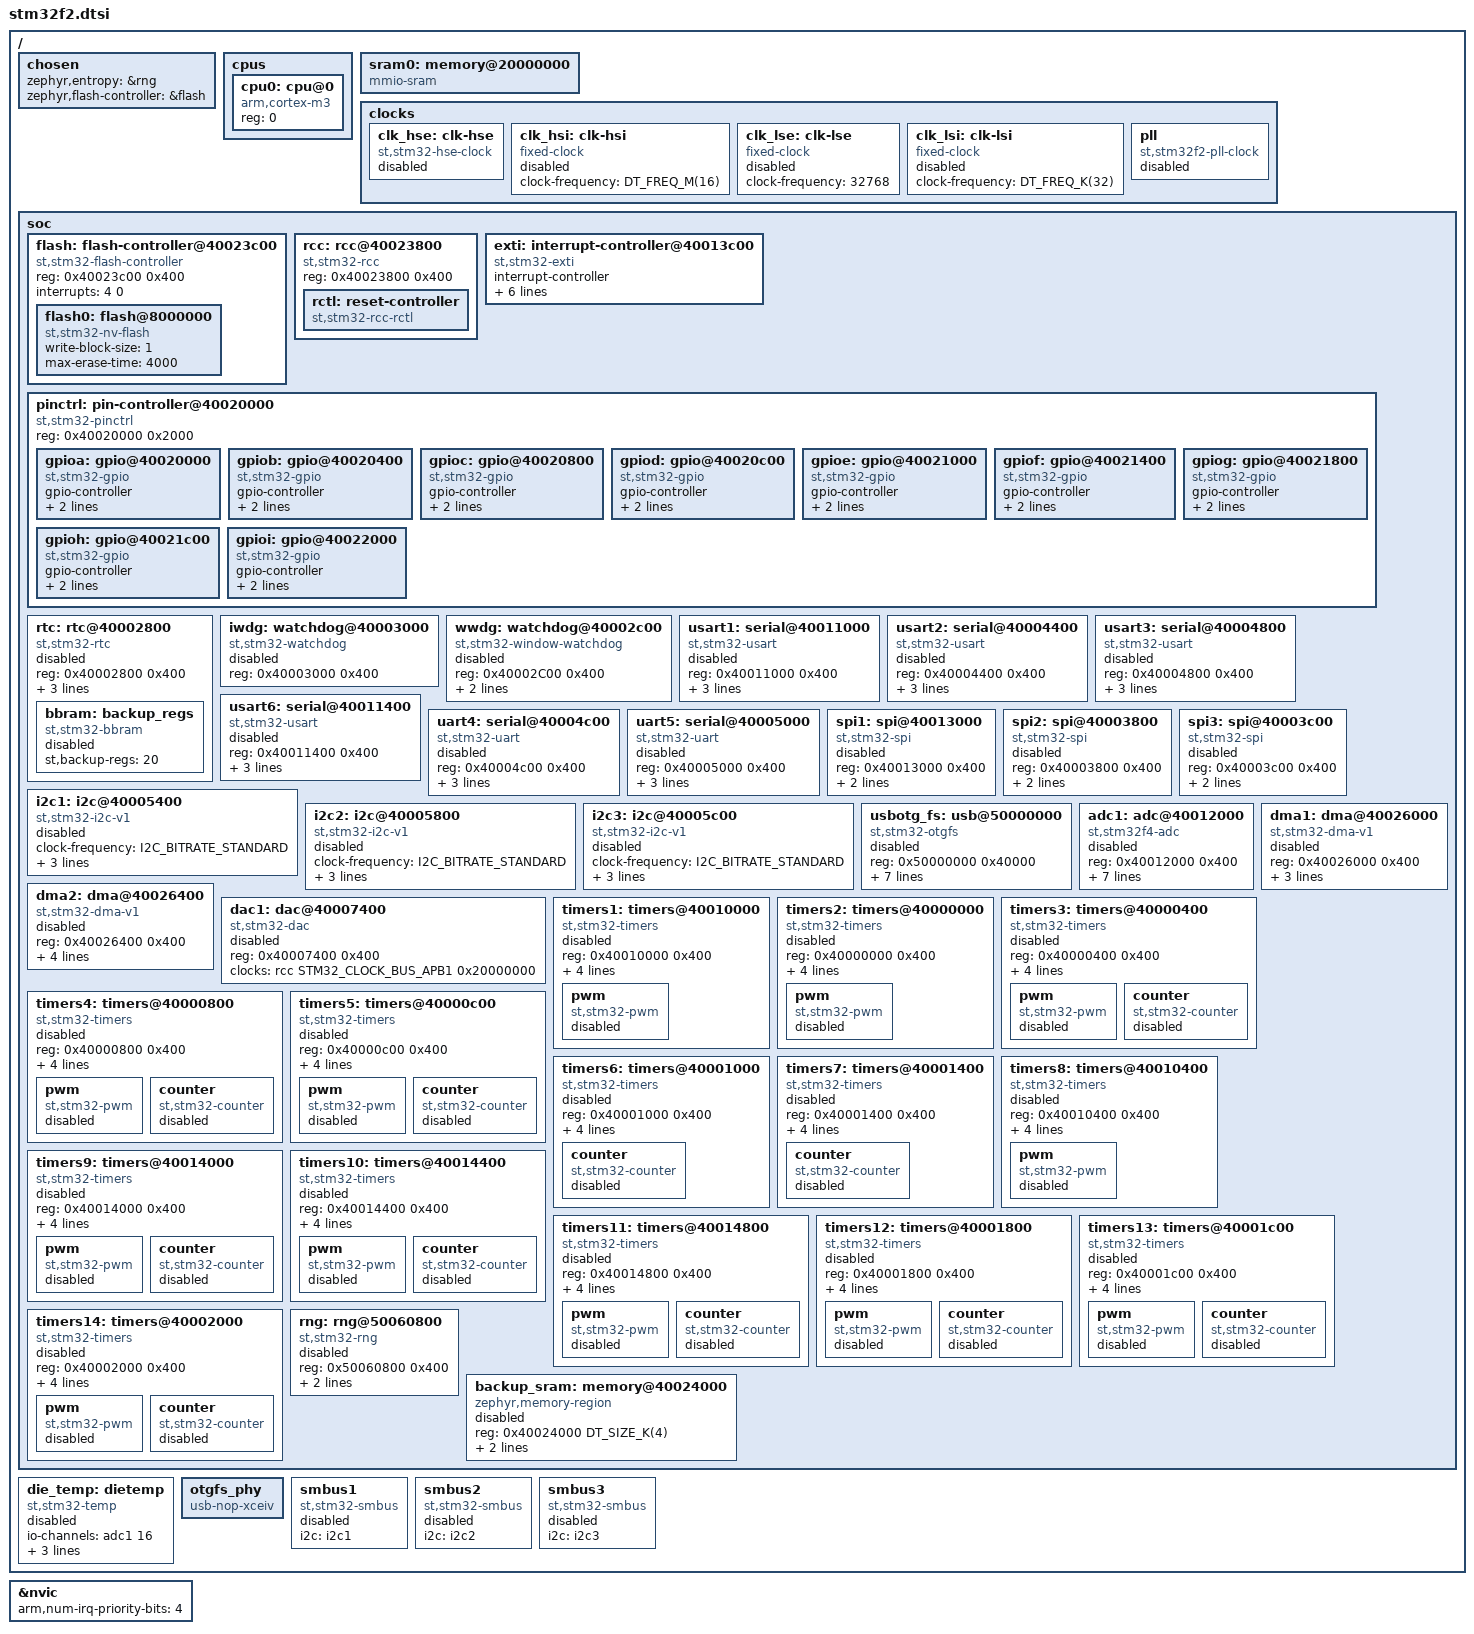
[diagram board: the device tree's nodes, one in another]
/*
 * Copyright (c) 2018 qianfan Zhao
 * Copyright (c) 2019 Centaur Analytics, Inc
 *
 * SPDX-License-Identifier: Apache-2.0
 */

#include <arm/armv7-m.dtsi>
#include <zephyr/dt-bindings/clock/stm32f4_clock.h>
#include <zephyr/dt-bindings/i2c/i2c.h>
#include <zephyr/dt-bindings/gpio/gpio.h>
#include <zephyr/dt-bindings/pwm/pwm.h>
#include <zephyr/dt-bindings/pwm/stm32_pwm.h>
#include <zephyr/dt-bindings/dma/stm32_dma.h>
#include <zephyr/dt-bindings/adc/stm32f4_adc.h>
#include <zephyr/dt-bindings/reset/stm32f2_4_7_reset.h>
#include <zephyr/dt-bindings/adc/adc.h>
#include <freq.h>

/ {
	chosen {
		zephyr,entropy = &rng;
		zephyr,flash-controller = &flash;
	};

	cpus {
		#address-cells = <1>;
		#size-cells = <0>;

		cpu0: cpu@0 {
			device_type = "cpu";
			compatible = "arm,cortex-m3";
			reg = <0>;
		};
	};

	sram0: memory@20000000 {
		compatible = "mmio-sram";
	};

	clocks {
		clk_hse: clk-hse {
			#clock-cells = <0>;
			compatible = "st,stm32-hse-clock";
			status = "disabled";
		};

		clk_hsi: clk-hsi {
			#clock-cells = <0>;
			compatible = "fixed-clock";
			clock-frequency = <DT_FREQ_M(16)>;
			status = "disabled";
		};

		clk_lse: clk-lse {
			#clock-cells = <0>;
			compatible = "fixed-clock";
			clock-frequency = <32768>;
			status = "disabled";
		};

		clk_lsi: clk-lsi {
			#clock-cells = <0>;
			compatible = "fixed-clock";
			clock-frequency = <DT_FREQ_K(32)>;
			status = "disabled";
		};

		pll: pll {
			#clock-cells = <0>;
			compatible = "st,stm32f2-pll-clock";
			status = "disabled";
		};
	};

	soc {
		flash: flash-controller@40023c00 {
			compatible = "st,stm32-flash-controller", "st,stm32f2-flash-controller";
			reg = <0x40023c00 0x400>;
			interrupts = <4 0>;

			#address-cells = <1>;
			#size-cells = <1>;

			flash0: flash@8000000 {
				compatible = "st,stm32-nv-flash", "soc-nv-flash";

				write-block-size = <1>;
				/* maximum erase time(ms) for a 128K sector */
				max-erase-time = <4000>;
			};
		};

		rcc: rcc@40023800 {
			compatible = "st,stm32-rcc";
			#clock-cells = <2>;
			reg = <0x40023800 0x400>;

			rctl: reset-controller {
				compatible = "st,stm32-rcc-rctl";
				#reset-cells = <1>;
			};
		};

		exti: interrupt-controller@40013c00 {
			compatible = "st,stm32-exti";
			interrupt-controller;
			#interrupt-cells = <1>;
			#address-cells = <1>;
			reg = <0x40013c00 0x400>;
			num-lines = <16>;
			interrupts = <6 0>, <7 0>, <8 0>, <9 0>,
				     <10 0>, <23 0>, <40 0>;
			interrupt-names = "line0", "line1", "line2", "line3",
					  "line4", "line5-9", "line10-15";
			line-ranges = <0 1>, <1 1>, <2 1>, <3 1>,
				      <4 1>, <5 5>, <10 6>;
		};

		pinctrl: pin-controller@40020000 {
			compatible = "st,stm32-pinctrl";
			#address-cells = <1>;
			#size-cells = <1>;
			reg = <0x40020000 0x2000>;

			gpioa: gpio@40020000 {
				compatible = "st,stm32-gpio";
				gpio-controller;
				#gpio-cells = <2>;
				reg = <0x40020000 0x400>;
				clocks = <&rcc STM32_CLOCK_BUS_AHB1 0x00000001>;
			};

			gpiob: gpio@40020400 {
				compatible = "st,stm32-gpio";
				gpio-controller;
				#gpio-cells = <2>;
				reg = <0x40020400 0x400>;
				clocks = <&rcc STM32_CLOCK_BUS_AHB1 0x00000002>;
			};

			gpioc: gpio@40020800 {
				compatible = "st,stm32-gpio";
				gpio-controller;
				#gpio-cells = <2>;
				reg = <0x40020800 0x400>;
				clocks = <&rcc STM32_CLOCK_BUS_AHB1 0x00000004>;
			};

			gpiod: gpio@40020c00 {
				compatible = "st,stm32-gpio";
				gpio-controller;
				#gpio-cells = <2>;
				reg = <0x40020c00 0x400>;
				clocks = <&rcc STM32_CLOCK_BUS_AHB1 0x00000008>;
			};

			gpioe: gpio@40021000 {
				compatible = "st,stm32-gpio";
				gpio-controller;
				#gpio-cells = <2>;
				reg = <0x40021000 0x400>;
				clocks = <&rcc STM32_CLOCK_BUS_AHB1 0x00000010>;
			};

			gpiof: gpio@40021400 {
				compatible = "st,stm32-gpio";
				gpio-controller;
				#gpio-cells = <2>;
				reg = <0x40021400 0x400>;
				clocks = <&rcc STM32_CLOCK_BUS_AHB1 0x00000020>;
			};

			gpiog: gpio@40021800 {
				compatible = "st,stm32-gpio";
				gpio-controller;
				#gpio-cells = <2>;
				reg = <0x40021800 0x400>;
				clocks = <&rcc STM32_CLOCK_BUS_AHB1 0x00000040>;
			};

			gpioh: gpio@40021c00 {
				compatible = "st,stm32-gpio";
				gpio-controller;
				#gpio-cells = <2>;
				reg = <0x40021c00 0x400>;
				clocks = <&rcc STM32_CLOCK_BUS_AHB1 0x00000080>;
			};

			gpioi: gpio@40022000 {
				compatible = "st,stm32-gpio";
				gpio-controller;
				#gpio-cells = <2>;
				reg = <0x40022000 0x400>;
				clocks = <&rcc STM32_CLOCK_BUS_AHB1 0x00000100>;
			};
		};

		rtc: rtc@40002800 {
			compatible = "st,stm32-rtc";
			reg = <0x40002800 0x400>;
			clocks = <&rcc STM32_CLOCK_BUS_APB1 0x10000000>;
			interrupts = <41 0>;
			prescaler = <32768>;
			status = "disabled";

			bbram: backup_regs {
				compatible = "st,stm32-bbram";
				st,backup-regs = <20>;
				status = "disabled";
			};
		};

		iwdg: watchdog@40003000 {
			compatible = "st,stm32-watchdog";
			reg = <0x40003000 0x400>;
			status = "disabled";
		};

		wwdg: watchdog@40002c00 {
			compatible = "st,stm32-window-watchdog";
			reg = <0x40002C00 0x400>;
			clocks = <&rcc STM32_CLOCK_BUS_APB1 0x00000800>;
			interrupts = <0 7>;
			status = "disabled";
		};

		usart1: serial@40011000 {
			compatible = "st,stm32-usart", "st,stm32-uart";
			reg = <0x40011000 0x400>;
			clocks = <&rcc STM32_CLOCK_BUS_APB2 0x00000010>;
			resets = <&rctl STM32_RESET(APB2, 4U)>;
			interrupts = <37 0>;
			status = "disabled";
		};

		usart2: serial@40004400 {
			compatible = "st,stm32-usart", "st,stm32-uart";
			reg = <0x40004400 0x400>;
			clocks = <&rcc STM32_CLOCK_BUS_APB1 0x00020000>;
			resets = <&rctl STM32_RESET(APB1, 17U)>;
			interrupts = <38 0>;
			status = "disabled";
		};

		usart3: serial@40004800 {
			compatible = "st,stm32-usart", "st,stm32-uart";
			reg = <0x40004800 0x400>;
			clocks = <&rcc STM32_CLOCK_BUS_APB1 0x00040000>;
			resets = <&rctl STM32_RESET(APB1, 18U)>;
			interrupts = <39 0>;
			status = "disabled";
		};

		usart6: serial@40011400 {
			compatible = "st,stm32-usart", "st,stm32-uart";
			reg = <0x40011400 0x400>;
			clocks = <&rcc STM32_CLOCK_BUS_APB2 0x00000020>;
			resets = <&rctl STM32_RESET(APB2, 5U)>;
			interrupts = <71 0>;
			status = "disabled";
		};

		uart4: serial@40004c00 {
			compatible ="st,stm32-uart";
			reg = <0x40004c00 0x400>;
			clocks = <&rcc STM32_CLOCK_BUS_APB1 0x00080000>;
			resets = <&rctl STM32_RESET(APB1, 19U)>;
			interrupts = <52 0>;
			status = "disabled";
		};

		uart5: serial@40005000 {
			compatible = "st,stm32-uart";
			reg = <0x40005000 0x400>;
			clocks = <&rcc STM32_CLOCK_BUS_APB1 0x00100000>;
			resets = <&rctl STM32_RESET(APB1, 20U)>;
			interrupts = <53 0>;
			status = "disabled";
		};

		spi1: spi@40013000 {
			compatible = "st,stm32-spi";
			#address-cells = <1>;
			#size-cells = <0>;
			reg = <0x40013000 0x400>;
			clocks = <&rcc STM32_CLOCK_BUS_APB2 0x00001000>;
			interrupts = <35 5>;
			status = "disabled";
		};

		spi2: spi@40003800 {
			compatible = "st,stm32-spi";
			#address-cells = <1>;
			#size-cells = <0>;
			reg = <0x40003800 0x400>;
			clocks = <&rcc STM32_CLOCK_BUS_APB1 0x00004000>;
			interrupts = <36 5>;
			status = "disabled";
		};

		spi3: spi@40003c00 {
			compatible = "st,stm32-spi";
			#address-cells = <1>;
			#size-cells = <0>;
			reg = <0x40003c00 0x400>;
			clocks = <&rcc STM32_CLOCK_BUS_APB1 0x00008000>;
			interrupts = <51 5>;
			status = "disabled";
		};

		i2c1: i2c@40005400 {
			compatible = "st,stm32-i2c-v1";
			clock-frequency = <I2C_BITRATE_STANDARD>;
			#address-cells = <1>;
			#size-cells = <0>;
			reg = <0x40005400 0x400>;
			clocks = <&rcc STM32_CLOCK_BUS_APB1 0x00200000>;
			interrupts = <31 0>, <32 0>;
			interrupt-names = "event", "error";
			status = "disabled";
		};

		i2c2: i2c@40005800 {
			compatible = "st,stm32-i2c-v1";
			clock-frequency = <I2C_BITRATE_STANDARD>;
			#address-cells = <1>;
			#size-cells = <0>;
			reg = <0x40005800 0x400>;
			clocks = <&rcc STM32_CLOCK_BUS_APB1 0x00400000>;
			interrupts = <33 0>, <34 0>;
			interrupt-names = "event", "error";
			status = "disabled";
		};

		i2c3: i2c@40005c00 {
			compatible = "st,stm32-i2c-v1";
			clock-frequency = <I2C_BITRATE_STANDARD>;
			#address-cells = <1>;
			#size-cells = <0>;
			reg = <0x40005c00 0x400>;
			clocks = <&rcc STM32_CLOCK_BUS_APB1 0x00800000>;
			interrupts = <72 0>, <73 0>;
			interrupt-names = "event", "error";
			status = "disabled";
		};

		usbotg_fs: usb@50000000 {
			compatible = "st,stm32-otgfs";
			reg = <0x50000000 0x40000>;
			interrupts = <67 0>;
			interrupt-names = "otgfs";
			num-bidir-endpoints = <4>;
			ram-size = <1280>;
			maximum-speed = "full-speed";
			clocks = <&rcc STM32_CLOCK_BUS_AHB2 0x00000080>,
				 <&rcc STM32_SRC_PLL_Q NO_SEL>;
			phys = <&otgfs_phy>;
			status = "disabled";
		};

		adc1: adc@40012000 {
			compatible = "st,stm32f4-adc", "st,stm32-adc";
			reg = <0x40012000 0x400>;
			clocks = <&rcc STM32_CLOCK_BUS_APB2 0x00000100>;
			interrupts = <18 0>;
			status = "disabled";
			#io-channel-cells = <1>;
			resolutions = <STM32_ADC_RES(12, 0x00)
				       STM32_ADC_RES(10, 0x01)
				       STM32_ADC_RES(8, 0x02)
				       STM32_ADC_RES(6, 0x03)>;
			sampling-times = <3 15 28 58 84 112 144 480>;
			st,adc-clock-source = <SYNC>;
			st,adc-sequencer = <FULLY_CONFIGURABLE>;
		};

		dma1: dma@40026000 {
			compatible = "st,stm32-dma-v1";
			#dma-cells = <4>;
			reg = <0x40026000 0x400>;
			interrupts = <11 0 12 0 13 0 14 0 15 0 16 0 17 0 47 0>;
			clocks = <&rcc STM32_CLOCK_BUS_AHB1 0x200000>;
			status = "disabled";
		};

		dma2: dma@40026400 {
			compatible = "st,stm32-dma-v1";
			#dma-cells = <4>;
			reg = <0x40026400 0x400>;
			interrupts = <56 0 57 0 58 0 59 0 60 0 68 0 69 0 70 0>;
			clocks = <&rcc STM32_CLOCK_BUS_AHB1 0x400000>;
			st,mem2mem;
			status = "disabled";
		};

		dac1: dac@40007400 {
			compatible = "st,stm32-dac";
			reg = <0x40007400 0x400>;
			clocks = <&rcc STM32_CLOCK_BUS_APB1 0x20000000>;
			status = "disabled";
			#io-channel-cells = <1>;
		};

		timers1: timers@40010000 {
			compatible = "st,stm32-timers";
			reg = <0x40010000 0x400>;
			clocks = <&rcc STM32_CLOCK_BUS_APB2 0x00000001>;
			resets = <&rctl STM32_RESET(APB2, 0U)>;
			interrupts = <24 0>, <25 0>, <26 0>, <27 0>;
			interrupt-names = "brk", "up", "trgcom", "cc";
			st,prescaler = <0>;
			status = "disabled";

			pwm {
				compatible = "st,stm32-pwm";
				status = "disabled";
				#pwm-cells = <3>;
			};
		};

		timers2: timers@40000000 {
			compatible = "st,stm32-timers";
			reg = <0x40000000 0x400>;
			clocks = <&rcc STM32_CLOCK_BUS_APB1 0x00000001>;
			resets = <&rctl STM32_RESET(APB1, 0U)>;
			interrupts = <28 0>;
			interrupt-names = "global";
			st,prescaler = <0>;
			status = "disabled";

			pwm {
				compatible = "st,stm32-pwm";
				status = "disabled";
				#pwm-cells = <3>;
			};
		};

		timers3: timers@40000400 {
			compatible = "st,stm32-timers";
			reg = <0x40000400 0x400>;
			clocks = <&rcc STM32_CLOCK_BUS_APB1 0x00000002>;
			resets = <&rctl STM32_RESET(APB1, 1U)>;
			interrupts = <29 0>;
			interrupt-names = "global";
			st,prescaler = <0>;
			status = "disabled";

			pwm {
				compatible = "st,stm32-pwm";
				status = "disabled";
				#pwm-cells = <3>;
			};

			counter {
				compatible = "st,stm32-counter";
				status = "disabled";
			};
		};

		timers4: timers@40000800 {
			compatible = "st,stm32-timers";
			reg = <0x40000800 0x400>;
			clocks = <&rcc STM32_CLOCK_BUS_APB1 0x00000004>;
			resets = <&rctl STM32_RESET(APB1, 2U)>;
			interrupts = <30 0>;
			interrupt-names = "global";
			st,prescaler = <0>;
			status = "disabled";

			pwm {
				compatible = "st,stm32-pwm";
				status = "disabled";
				#pwm-cells = <3>;
			};

			counter {
				compatible = "st,stm32-counter";
				status = "disabled";
			};
		};

		timers5: timers@40000c00 {
			compatible = "st,stm32-timers";
			reg = <0x40000c00 0x400>;
			clocks = <&rcc STM32_CLOCK_BUS_APB1 0x00000008>;
			resets = <&rctl STM32_RESET(APB1, 3U)>;
			interrupts = <50 0>;
			interrupt-names = "global";
			st,prescaler = <0>;
			status = "disabled";

			pwm {
				compatible = "st,stm32-pwm";
				status = "disabled";
				#pwm-cells = <3>;
			};

			counter {
				compatible = "st,stm32-counter";
				status = "disabled";
			};
		};

		timers6: timers@40001000 {
			compatible = "st,stm32-timers";
			reg = <0x40001000 0x400>;
			clocks = <&rcc STM32_CLOCK_BUS_APB1 0x00000010>;
			resets = <&rctl STM32_RESET(APB1, 4U)>;
			interrupts = <54 0>;
			interrupt-names = "global";
			st,prescaler = <0>;
			status = "disabled";

			counter {
				compatible = "st,stm32-counter";
				status = "disabled";
			};
		};

		timers7: timers@40001400 {
			compatible = "st,stm32-timers";
			reg = <0x40001400 0x400>;
			clocks = <&rcc STM32_CLOCK_BUS_APB1 0x00000020>;
			resets = <&rctl STM32_RESET(APB1, 5U)>;
			interrupts = <55 0>;
			interrupt-names = "global";
			st,prescaler = <0>;
			status = "disabled";

			counter {
				compatible = "st,stm32-counter";
				status = "disabled";
			};
		};

		timers8: timers@40010400 {
			compatible = "st,stm32-timers";
			reg = <0x40010400 0x400>;
			clocks = <&rcc STM32_CLOCK_BUS_APB2 0x00000002>;
			resets = <&rctl STM32_RESET(APB2, 1U)>;
			interrupts = <43 0>, <44 0>, <45 0>, <46 0>;
			interrupt-names = "brk", "up", "trgcom", "cc";
			st,prescaler = <0>;
			status = "disabled";

			pwm {
				compatible = "st,stm32-pwm";
				status = "disabled";
				#pwm-cells = <3>;
			};
		};

		timers9: timers@40014000 {
			compatible = "st,stm32-timers";
			reg = <0x40014000 0x400>;
			clocks = <&rcc STM32_CLOCK_BUS_APB2 0x00010000>;
			resets = <&rctl STM32_RESET(APB2, 16U)>;
			interrupts = <24 0>;
			interrupt-names = "global";
			st,prescaler = <0>;
			status = "disabled";

			pwm {
				compatible = "st,stm32-pwm";
				status = "disabled";
				#pwm-cells = <3>;
			};

			counter {
				compatible = "st,stm32-counter";
				status = "disabled";
			};
		};

		timers10: timers@40014400 {
			compatible = "st,stm32-timers";
			reg = <0x40014400 0x400>;
			clocks = <&rcc STM32_CLOCK_BUS_APB2 0x00020000>;
			resets = <&rctl STM32_RESET(APB2, 17U)>;
			interrupts = <25 0>;
			interrupt-names = "global";
			st,prescaler = <0>;
			status = "disabled";

			pwm {
				compatible = "st,stm32-pwm";
				status = "disabled";
				#pwm-cells = <3>;
			};

			counter {
				compatible = "st,stm32-counter";
				status = "disabled";
			};
		};

		timers11: timers@40014800 {
			compatible = "st,stm32-timers";
			reg = <0x40014800 0x400>;
			clocks = <&rcc STM32_CLOCK_BUS_APB2 0x00040000>;
			resets = <&rctl STM32_RESET(APB2, 18U)>;
			interrupts = <26 0>;
			interrupt-names = "global";
			st,prescaler = <0>;
			status = "disabled";

			pwm {
				compatible = "st,stm32-pwm";
				status = "disabled";
				#pwm-cells = <3>;
			};

			counter {
				compatible = "st,stm32-counter";
				status = "disabled";
			};
		};

		timers12: timers@40001800 {
			compatible = "st,stm32-timers";
			reg = <0x40001800 0x400>;
			clocks = <&rcc STM32_CLOCK_BUS_APB1 0x00000040>;
			resets = <&rctl STM32_RESET(APB1, 6U)>;
			interrupts = <43 0>;
			interrupt-names = "global";
			st,prescaler = <0>;
			status = "disabled";

			pwm {
				compatible = "st,stm32-pwm";
				status = "disabled";
				#pwm-cells = <3>;
			};

			counter {
				compatible = "st,stm32-counter";
				status = "disabled";
			};
		};

		timers13: timers@40001c00 {
			compatible = "st,stm32-timers";
			reg = <0x40001c00 0x400>;
			clocks = <&rcc STM32_CLOCK_BUS_APB1 0x00000080>;
			resets = <&rctl STM32_RESET(APB1, 7U)>;
			interrupts = <44 0>;
			interrupt-names = "global";
			st,prescaler = <0>;
			status = "disabled";

			pwm {
				compatible = "st,stm32-pwm";
				status = "disabled";
				#pwm-cells = <3>;
			};

			counter {
				compatible = "st,stm32-counter";
				status = "disabled";
			};
		};

		timers14: timers@40002000 {
			compatible = "st,stm32-timers";
			reg = <0x40002000 0x400>;
			clocks = <&rcc STM32_CLOCK_BUS_APB1 0x00000100>;
			resets = <&rctl STM32_RESET(APB1, 8U)>;
			interrupts = <45 0>;
			interrupt-names = "global";
			st,prescaler = <0>;
			status = "disabled";

			pwm {
				compatible = "st,stm32-pwm";
				status = "disabled";
				#pwm-cells = <3>;
			};

			counter {
				compatible = "st,stm32-counter";
				status = "disabled";
			};
		};

		rng: rng@50060800 {
			compatible = "st,stm32-rng";
			reg = <0x50060800 0x400>;
			interrupts = <80 0>;
			clocks = <&rcc STM32_CLOCK_BUS_AHB2 0x00000040>;
			status = "disabled";
		};

		backup_sram: memory@40024000 {
			compatible = "zephyr,memory-region", "st,stm32-backup-sram";
			reg = <0x40024000 DT_SIZE_K(4)>;
			clocks = <&rcc STM32_CLOCK_BUS_AHB1 0x00040000>;
			zephyr,memory-region = "BACKUP_SRAM";
			status = "disabled";
		};
	};

	die_temp: dietemp {
		compatible = "st,stm32-temp";
		io-channels = <&adc1 16>;
		status = "disabled";
		v25 = <760>;
		ntc;
		avgslope = <25>;
	};

	otgfs_phy: otgfs_phy {
		compatible = "usb-nop-xceiv";
		#phy-cells = <0>;
	};

	smbus1: smbus1 {
		compatible = "st,stm32-smbus";
		#address-cells = <1>;
		#size-cells = <0>;
		i2c = <&i2c1>;
		status = "disabled";
	};

	smbus2: smbus2 {
		compatible = "st,stm32-smbus";
		#address-cells = <1>;
		#size-cells = <0>;
		i2c = <&i2c2>;
		status = "disabled";
	};

	smbus3: smbus3 {
		compatible = "st,stm32-smbus";
		#address-cells = <1>;
		#size-cells = <0>;
		i2c = <&i2c3>;
		status = "disabled";
	};
};

&nvic {
	arm,num-irq-priority-bits = <4>;
};
